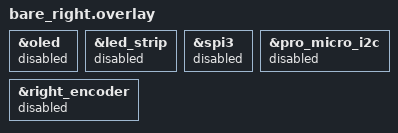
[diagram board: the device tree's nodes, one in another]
/*
 * Copyright (c) 2026 PandaKB
 * SPDX-License-Identifier: MIT
 */

/* Disable OLED + underglow devices so they cannot claim buses/GPIOs. */
&oled {
    status = "disabled";
};

&led_strip {
    status = "disabled";
};

&spi3 {
    status = "disabled";
};

&pro_micro_i2c {
    status = "disabled";
};

/* Encoder still listed in sensors; disable it when EC11 is off. */
&right_encoder {
    status = "disabled";
};
